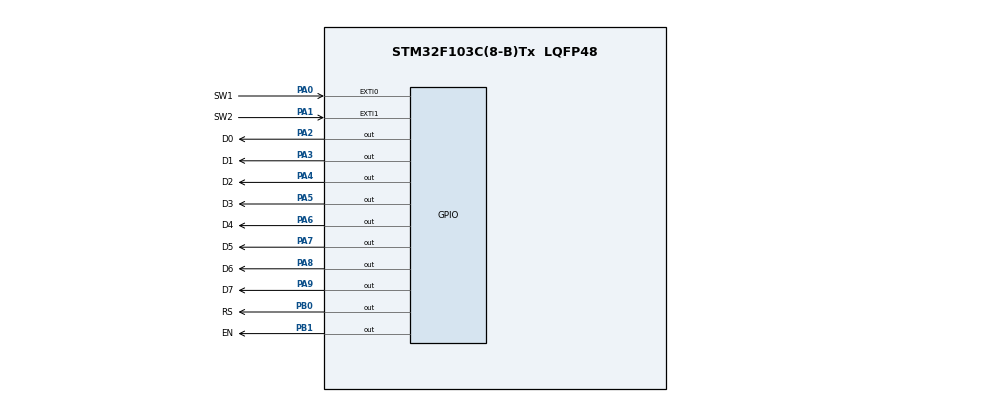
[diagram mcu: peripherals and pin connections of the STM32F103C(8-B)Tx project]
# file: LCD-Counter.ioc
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Mcu.Family=STM32F1
Mcu.Name=STM32F103C(8-B)Tx
Mcu.Package=LQFP48
NVIC.EXTI0_IRQn=true\:1\:0\:true
NVIC.EXTI1_IRQn=true\:2\:0\:true
NVIC.PriorityGroup=NVIC_PRIORITYGROUP_4
PA0-WKUP.GPIO_Label=SW1
PA0-WKUP.GPIO_ModeDefaultEXTI=GPIO_MODE_IT_RISING
PA0-WKUP.GPIO_PuPd=GPIO_PULLDOWN
PA0-WKUP.Signal=GPXTI0
PA1.GPIO_Label=SW2
PA1.GPIO_ModeDefaultEXTI=GPIO_MODE_IT_RISING
PA1.GPIO_PuPd=GPIO_PULLDOWN
PA1.Signal=GPXTI1
PA2.GPIO_Label=D0
PA2.GPIO_ModeDefaultOutputPP=GPIO_MODE_OUTPUT_PP
PA2.GPIO_Speed=GPIO_SPEED_LOW
PA2.Signal=GPIO_Output
PA3.GPIO_Label=D1
PA3.GPIO_ModeDefaultOutputPP=GPIO_MODE_OUTPUT_PP
PA3.GPIO_Speed=GPIO_SPEED_LOW
PA3.Signal=GPIO_Output
PA4.GPIO_Label=D2
PA4.GPIO_ModeDefaultOutputPP=GPIO_MODE_OUTPUT_PP
PA4.GPIO_Speed=GPIO_SPEED_LOW
PA4.Signal=GPIO_Output
PA5.GPIO_Label=D3
PA5.GPIO_ModeDefaultOutputPP=GPIO_MODE_OUTPUT_PP
PA5.GPIO_Speed=GPIO_SPEED_LOW
PA5.Signal=GPIO_Output
PA6.GPIO_Label=D4
PA6.GPIO_ModeDefaultOutputPP=GPIO_MODE_OUTPUT_PP
PA6.GPIO_Speed=GPIO_SPEED_LOW
PA6.Signal=GPIO_Output
PA7.GPIO_Label=D5
PA7.GPIO_ModeDefaultOutputPP=GPIO_MODE_OUTPUT_PP
PA7.GPIO_Speed=GPIO_SPEED_LOW
PA7.Signal=GPIO_Output
PA8.GPIO_Label=D6
PA8.Signal=GPIO_Output
PA9.GPIO_Label=D7
PA9.Signal=GPIO_Output
PB0.GPIO_Label=RS
PB0.Signal=GPIO_Output
PB1.GPIO_Label=EN
PB1.Signal=GPIO_Output
ProjectManager.TargetToolchain=EWARM
RCC.APB1Freq_Value=8000000
RCC.APB2Freq_Value=8000000

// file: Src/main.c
/**
  ******************************************************************************
  * File Name          : main.c
  * Date               : 09/09/2020 22:58:47
  * Description        : Main program body
  ******************************************************************************
  *
  * COPYRIGHT(c) 2020 STMicroelectronics
  *
  * Redistribution and use in source and binary forms, with or without modification,
  * are permitted provided that the following conditions are met:
  *   1. Redistributions of source code must retain the above copyright notice,
  *      this list of conditions and the following disclaimer.
  *   2. Redistributions in binary form must reproduce the above copyright notice,
  *      this list of conditions and the following disclaimer in the documentation
  *      and/or other materials provided with the distribution.
  *   3. Neither the name of STMicroelectronics nor the names of its contributors
  *      may be used to endorse or promote products derived from this software
  *      without specific prior written permission.
  *
  * THIS SOFTWARE IS PROVIDED BY THE COPYRIGHT HOLDERS AND CONTRIBUTORS "AS IS"
  * AND ANY EXPRESS OR IMPLIED WARRANTIES, INCLUDING, BUT NOT LIMITED TO, THE
  * IMPLIED WARRANTIES OF MERCHANTABILITY AND FITNESS FOR A PARTICULAR PURPOSE ARE
  * DISCLAIMED. IN NO EVENT SHALL THE COPYRIGHT HOLDER OR CONTRIBUTORS BE LIABLE
  * FOR ANY DIRECT, INDIRECT, INCIDENTAL, SPECIAL, EXEMPLARY, OR CONSEQUENTIAL
  * DAMAGES (INCLUDING, BUT NOT LIMITED TO, PROCUREMENT OF SUBSTITUTE GOODS OR
  * SERVICES; LOSS OF USE, DATA, OR PROFITS; OR BUSINESS INTERRUPTION) HOWEVER
  * CAUSED AND ON ANY THEORY OF LIABILITY, WHETHER IN CONTRACT, STRICT LIABILITY,
  * OR TORT (INCLUDING NEGLIGENCE OR OTHERWISE) ARISING IN ANY WAY OUT OF THE USE
  * OF THIS SOFTWARE, EVEN IF ADVISED OF THE POSSIBILITY OF SUCH DAMAGE.
  *
  ******************************************************************************
  */

#include "stm32f1xx_hal.h"

/* USER CODE BEGIN Includes */
#include <stdio.h>
#include "lcd.h"
int num = 0;
char text[16];
int flag = 0;
/* USER CODE END Includes */

void SystemClock_Config(void);
static void MX_GPIO_Init(void);

int main(void)
{

  /* MCU Configuration----------------------------------------------------------*/

  /* Reset of all peripherals, Initializes the Flash interface and the Systick. */
  HAL_Init();

  /* Configure the system clock */
  SystemClock_Config();

  /* Initialize all configured peripherals */
  MX_GPIO_Init();

  /* USER CODE BEGIN 2 */
  lcd_init();
  lcd_puts("Hello");
  /* USER CODE END 2 */

  /* Infinite loop */
  /* USER CODE BEGIN WHILE */
  while (1)
  {
    sprintf(text,"%d",num);
    if (flag == 1)
    {
      lcd_puts(text);
      flag = 0;
    }
  /* USER CODE END WHILE */

  }

}

/** System Clock Configuration
*/
void SystemClock_Config(void)
{

  RCC_OscInitTypeDef RCC_OscInitStruct;
  RCC_ClkInitTypeDef RCC_ClkInitStruct;

  RCC_OscInitStruct.OscillatorType = RCC_OSCILLATORTYPE_HSI;
  RCC_OscInitStruct.HSIState = RCC_HSI_ON;
  RCC_OscInitStruct.HSICalibrationValue = 16;
  RCC_OscInitStruct.PLL.PLLState = RCC_PLL_NONE;
  HAL_RCC_OscConfig(&RCC_OscInitStruct);

  RCC_ClkInitStruct.ClockType = RCC_CLOCKTYPE_SYSCLK;
  RCC_ClkInitStruct.SYSCLKSource = RCC_SYSCLKSOURCE_HSI;
  RCC_ClkInitStruct.AHBCLKDivider = RCC_SYSCLK_DIV1;
  RCC_ClkInitStruct.APB1CLKDivider = RCC_HCLK_DIV1;
  RCC_ClkInitStruct.APB2CLKDivider = RCC_HCLK_DIV1;
  HAL_RCC_ClockConfig(&RCC_ClkInitStruct, FLASH_LATENCY_0);

}

/** Configure pins as
        * Analog
        * Input
        * Output
        * EVENT_OUT
        * EXTI
*/
void MX_GPIO_Init(void)
{

  GPIO_InitTypeDef GPIO_InitStruct;

  /* GPIO Ports Clock Enable */
  __GPIOA_CLK_ENABLE();
  __GPIOB_CLK_ENABLE();

  /*Configure GPIO pins : PA0 PA1 */
  GPIO_InitStruct.Pin = GPIO_PIN_0|GPIO_PIN_1;
  GPIO_InitStruct.Mode = GPIO_MODE_IT_RISING;
  GPIO_InitStruct.Pull = GPIO_PULLDOWN;
  HAL_GPIO_Init(GPIOA, &GPIO_InitStruct);

  /*Configure GPIO pins : PA2 PA3 PA4 PA5
                           PA6 PA7 PA8 PA9 */
  GPIO_InitStruct.Pin = GPIO_PIN_2|GPIO_PIN_3|GPIO_PIN_4|GPIO_PIN_5
                          |GPIO_PIN_6|GPIO_PIN_7|GPIO_PIN_8|GPIO_PIN_9;
  GPIO_InitStruct.Mode = GPIO_MODE_OUTPUT_PP;
  GPIO_InitStruct.Speed = GPIO_SPEED_LOW;
  HAL_GPIO_Init(GPIOA, &GPIO_InitStruct);

  /*Configure GPIO pins : PB0 PB1 */
  GPIO_InitStruct.Pin = GPIO_PIN_0|GPIO_PIN_1;
  GPIO_InitStruct.Mode = GPIO_MODE_OUTPUT_PP;
  GPIO_InitStruct.Speed = GPIO_SPEED_LOW;
  HAL_GPIO_Init(GPIOB, &GPIO_InitStruct);

  /* EXTI interrupt init*/
  HAL_NVIC_SetPriority(EXTI1_IRQn, 2, 0);
  HAL_NVIC_EnableIRQ(EXTI1_IRQn);

  HAL_NVIC_SetPriority(EXTI0_IRQn, 1, 0);
  HAL_NVIC_EnableIRQ(EXTI0_IRQn);

}

/************************ (C) COPYRIGHT STMicroelectronics *****END OF FILE****/
